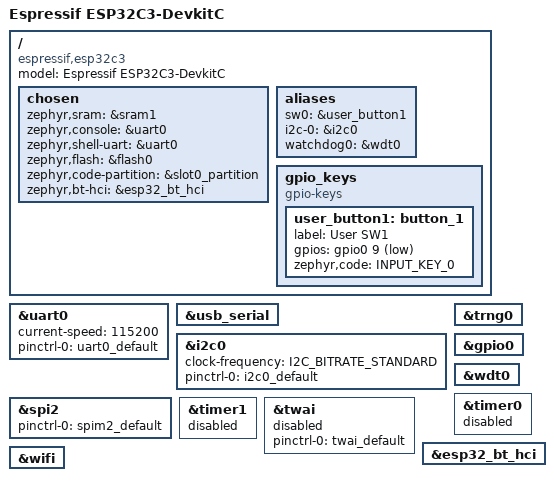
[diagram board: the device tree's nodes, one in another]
/*
 * Copyright (c) 2024 Espressif Systems (Shanghai) Co., Ltd.
 *
 * SPDX-License-Identifier: Apache-2.0
 */

/dts-v1/;

#include <espressif/esp32c3/esp32c3_wroom_n4.dtsi>
#include "esp32c3_devkitc-pinctrl.dtsi"
#include <zephyr/dt-bindings/input/input-event-codes.h>
#include <espressif/partitions_0x0_default.dtsi>

/ {
	compatible = "espressif,esp32c3";
	model = "Espressif ESP32C3-DevkitC";

	chosen {
		zephyr,sram = &sram1;
		zephyr,console = &uart0;
		zephyr,shell-uart = &uart0;
		zephyr,flash = &flash0;
		zephyr,code-partition = &slot0_partition;
		zephyr,bt-hci = &esp32_bt_hci;
	};

	aliases {
		sw0 = &user_button1;
		i2c-0 = &i2c0;
		watchdog0 = &wdt0;
	};

	gpio_keys {
		compatible = "gpio-keys";

		user_button1: button_1 {
			label = "User SW1";
			gpios = <&gpio0 9 (GPIO_PULL_UP | GPIO_ACTIVE_LOW)>;
			zephyr,code = <INPUT_KEY_0>;
		};
	};
};

&uart0 {
	current-speed = <115200>;
	pinctrl-0 = <&uart0_default>;
	pinctrl-names = "default";
	status = "okay";
};

&usb_serial {
	/* requires resoldering of resistors on the board */
	status = "okay";
};

&i2c0 {
	clock-frequency = <I2C_BITRATE_STANDARD>;
	pinctrl-0 = <&i2c0_default>;
	pinctrl-names = "default";
	status = "okay";
};

&trng0 {
	status = "okay";
};

&spi2 {
	#address-cells = <1>;
	#size-cells = <0>;
	pinctrl-0 = <&spim2_default>;
	pinctrl-names = "default";
	status = "okay";
};

&gpio0 {
	status = "okay";
};

&wdt0 {
	status = "okay";
};

&timer0 {
	status = "disabled";
};

&timer1 {
	status = "disabled";
};

&twai {
	pinctrl-0 = <&twai_default>;
	pinctrl-names = "default";
	/* requires external CAN transceiver or jumper on RX and TX pins for loopback testing */
	status = "disabled";
};

&esp32_bt_hci {
	status = "okay";
};

&wifi {
	status = "okay";
};
